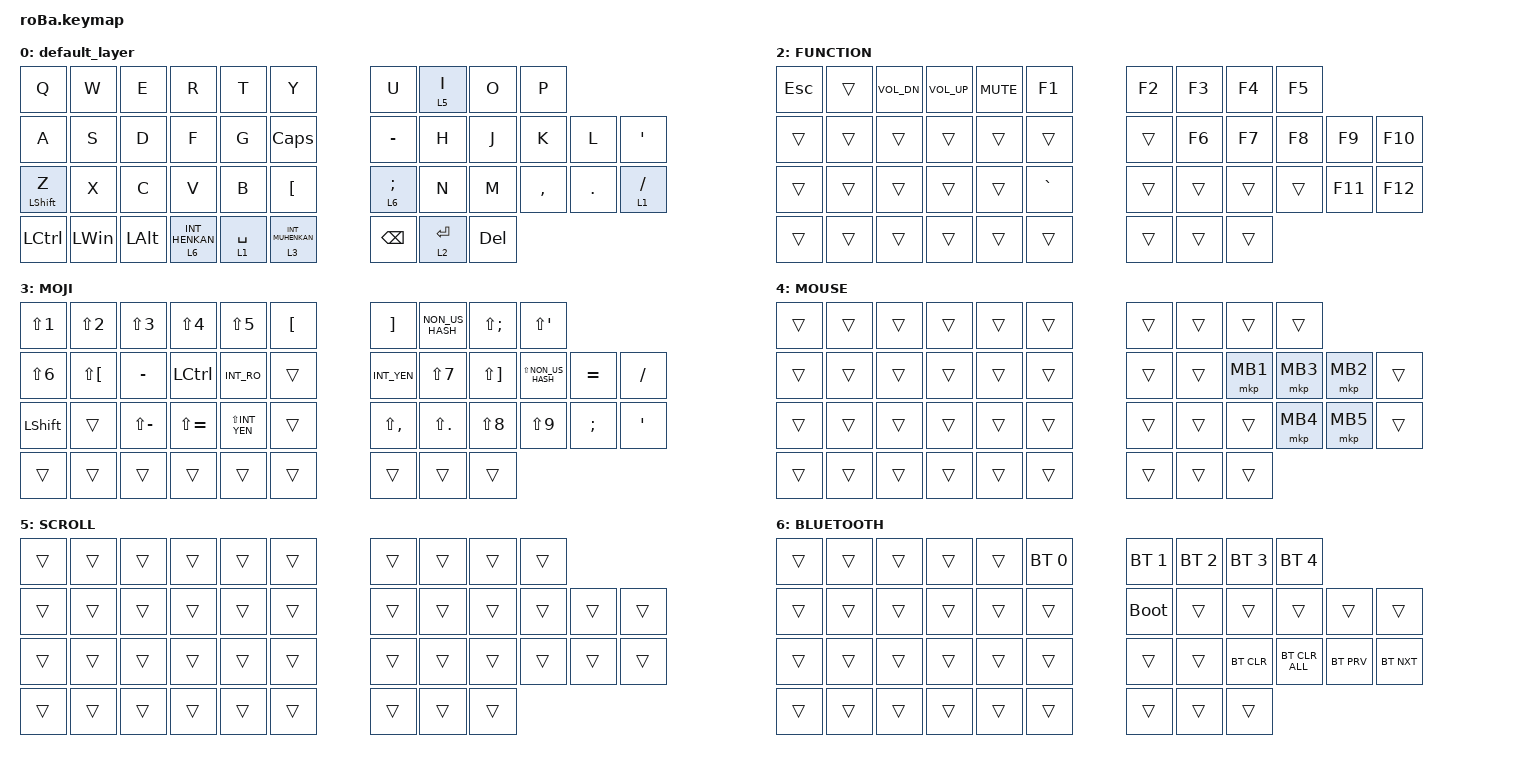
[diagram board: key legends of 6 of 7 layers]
#define ZMK_POINTING_DEFAULT_SCRL_VAL 80

#include <input/processors.dtsi>
#include <behaviors.dtsi>
#include <dt-bindings/zmk/bt.h>
#include <dt-bindings/zmk/keys.h>
#include <dt-bindings/zmk/pointing.h>

&mt {
    flavor = "balanced";
    quick-tap-ms = <0>;
};

&trackball {
    scroll-layers = <5>;

    // arrows {
    //     layers = <3>;
    //     bindings =
    //         <&kp RIGHT_ARROW>,
    //         <&kp LEFT_ARROW>,
    //         <&kp UP_ARROW>,
    //         <&kp DOWN_ARROW>;
    //     tick = <10>;
    //     wait-ms = <5>;
    //     tap-ms = <5>;
    // };
};

/ {
    combos {
        compatible = "zmk,combos";

        tab {
            bindings = <&kp TAB>;
            key-positions = <11 12>;
        };

        shift_tab {
            bindings = <&kp LS(TAB)>;
            key-positions = <12 13>;
        };

        muhennkann {
            bindings = <&to_layer_0 INT_MUHENKAN>;
            key-positions = <11 10>;
        };

        double_quotation {
            bindings = <&kp LS(N2)>;
            key-positions = <20 21>;
        };

        eq {
            bindings = <&kp LS(MINUS)>;
            key-positions = <24 25>;
        };

        henkan {
            bindings = <&kp CAPSLOCK>;
            key-positions = <0 1>;
        };
    };

    macros {
        to_layer_0: to_layer_0 {
            compatible = "zmk,behavior-macro-one-param";
            #binding-cells = <1>;
            bindings = <&to 0 &macro_param_1to1 &kp MACRO_PLACEHOLDER>;
            label = "TO_LAYER_0";
        };
    };

    behaviors {
        lt_to_layer_0: lt_to_layer_0 {
            compatible = "zmk,behavior-hold-tap";
            label = "LAYER_TAP_TO_0";
            bindings = <&mo>, <&to_layer_0>;

            #binding-cells = <2>;
            tapping-term-ms = <200>;
        };

        encoder_msc_down_up: encoder_msc_down_up {
            compatible = "zmk,behavior-sensor-rotate";
            label = "ENCODER_MSC_DOWN_UP";
            #sensor-binding-cells = <0>;
            bindings = <&msc SCRL_DOWN>, <&msc SCRL_UP>;

            tap-ms = <20>;
        };
    };

    keymap {
        compatible = "zmk,keymap";

        default_layer {
            bindings = <
&kp Q             &kp W         &kp E         &kp R                        &kp T        &kp Y                          &kp U            &lt 5 I      &kp O    &kp P
&kp A             &kp S         &kp D         &kp F                        &kp G        &kp CAPS                       &kp MINUS        &kp H        &kp J    &kp K      &kp L    &kp SINGLE_QUOTE
&mt LEFT_SHIFT Z  &kp X         &kp C         &kp V                        &kp B        &kp LEFT_BRACKET               &lt 6 SEMICOLON  &kp N        &kp M    &kp COMMA  &kp DOT  &lt 1 SLASH
&kp LCTRL         &kp LEFT_WIN  &kp LEFT_ALT  &lt_to_layer_0 6 INT_HENKAN  &lt 1 SPACE  &lt_to_layer_0 3 INT_MUHENKAN  &kp BACKSPACE    &lt 2 ENTER  &kp DEL
            >;

            sensor-bindings = <&encoder_msc_down_up>;
        };

        NUM-ARROW {
            bindings = <
&kp MINUS          &kp N7  &kp N8  &kp N9  &kp SLASH             &kp LG(UP_ARROW)  &kp HOME                &trans                   &kp END         &trans
&kp LS(SEMICOLON)  &kp N4  &kp N5  &kp N6  &kp LS(SINGLE_QUOTE)  &trans            &kp LG(LEFT_ARROW)      &kp LG(RIGHT_ARROW)      &kp LEFT_ARROW  &kp UP_ARROW    &kp RIGHT_ARROW  &trans
&kp N0             &kp N1  &kp N2  &kp N3  &kp PERIOD            &kp LS(MINUS)     &kp LG(LS(LEFT_ARROW))  &kp LG(LS(RIGHT_ARROW))  &kp PAGE_UP     &kp DOWN_ARROW  &kp PAGE_DOWN    &trans
            >;
        };

        FUNCTION {
            bindings = <
&kp ESC  &trans  &kp C_VOL_DN  &kp C_VOL_UP  &kp C_MUTE  &kp F1  &kp F2  &kp F3  &kp F4  &kp F5
&trans  &trans  &trans  &trans  &trans  &trans  &trans  &kp F6  &kp F7  &kp F8  &kp F9   &kp F10
&trans  &trans  &trans  &trans  &trans  &kp GRAVE  &trans  &trans  &trans  &trans  &kp F11  &kp F12
&trans  &trans  &trans  &trans  &trans  &trans  &trans  &trans  &trans
            >;
        };

        MOJI {
            bindings = <
&kp LS(N1)      &kp LS(N2)            &kp LS(N3)     &kp LS(N4)     &kp LS(N5)       &kp LEFT_BRACKET  &kp RIGHT_BRACKET  &kp NON_US_HASH  &kp LS(SEMICOLON)      &kp LS(SINGLE_QUOTE)
&kp LS(N6)      &kp LS(LEFT_BRACKET)  &kp MINUS      &kp LCTRL      &kp INT_RO       &trans            &kp INT_YEN        &kp LS(N7)       &kp LS(RIGHT_BRACKET)  &kp LS(NON_US_HASH)   &kp EQUAL      &kp SLASH
&kp LEFT_SHIFT  &trans                &kp LS(MINUS)  &kp LS(EQUAL)  &kp LS(INT_YEN)  &trans            &kp LS(COMMA)      &kp LS(DOT)      &kp LS(N8)             &kp LS(N9)            &kp SEMICOLON  &kp SINGLE_QUOTE
&trans          &trans                &trans         &trans         &trans           &trans            &trans             &trans           &trans
            >;
        };

        MOUSE {
            bindings = <
&trans  &trans  &trans  &trans  &trans  &trans  &trans  &trans  &trans    &trans
&trans  &trans  &trans  &trans  &trans  &trans  &trans  &trans  &mkp MB1  &mkp MB3  &mkp MB2  &trans
&trans  &trans  &trans  &trans  &trans  &trans  &trans  &trans  &trans    &mkp MB4  &mkp MB5  &trans
&trans  &trans  &trans  &trans  &trans  &trans  &trans  &trans  &trans
            >;
        };

        SCROLL {
            bindings = <
&trans  &trans  &trans  &trans  &trans  &trans  &trans  &trans  &trans  &trans
&trans  &trans  &trans  &trans  &trans  &trans  &trans  &trans  &trans  &trans  &trans  &trans
&trans  &trans  &trans  &trans  &trans  &trans  &trans  &trans  &trans  &trans  &trans  &trans
&trans  &trans  &trans  &trans  &trans  &trans  &trans  &trans  &trans
            >;
        };

        BLUETOOTH {
            bindings = <
&trans  &trans  &trans  &trans  &trans  &bt BT_SEL 0  &bt BT_SEL 1  &bt BT_SEL 2  &bt BT_SEL 3  &bt BT_SEL 4
&trans  &trans  &trans  &trans  &trans  &trans        &bootloader   &trans        &trans        &trans          &trans      &trans
&trans  &trans  &trans  &trans  &trans  &trans        &trans        &trans        &bt BT_CLR    &bt BT_CLR_ALL  &bt BT_PRV  &bt BT_NXT
&trans  &trans  &trans  &trans  &trans  &trans        &trans        &trans        &trans
            >;
        };
    };
};
